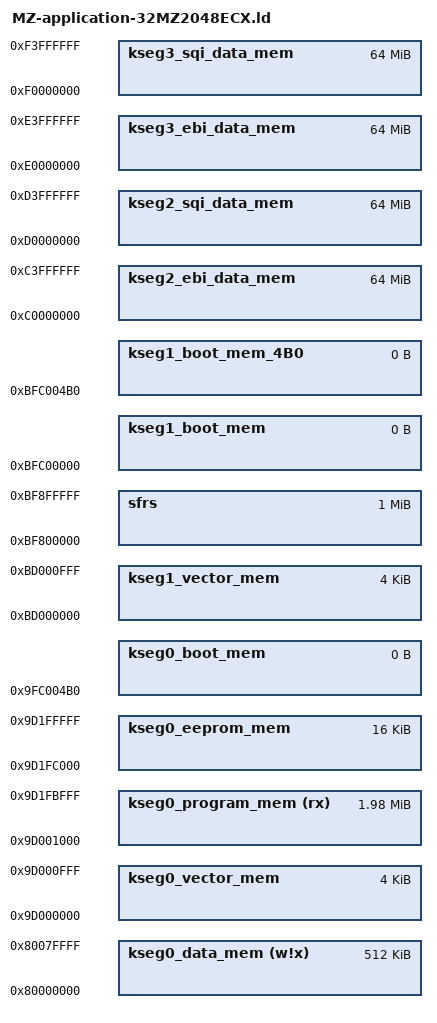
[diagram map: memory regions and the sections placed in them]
/*--------------------------------------------------------------------------
 * MPLAB XC Compiler -  PIC32MZ2048ECH100 linker script
 *
 * This software is developed by Microchip Technology Inc. and its
 * subsidiaries ("Microchip").
 *
 * Redistribution and use in source and binary forms, with or without
 * modification, are permitted provided that the following conditions are
 * met:
 *
 * 1.      Redistributions of source code must retain the above copyright
 *         notice, this list of conditions and the following disclaimer.
 * 2.      Redistributions in binary form must reproduce the above
 *         copyright notice, this list of conditions and the following
 *         disclaimer in the documentation and/or other materials provided
 *         with the distribution.
 * 3.      Microchip's name may not be used to endorse or promote products
 *         derived from this software without specific prior written
 *         permission.
 *
 * THIS SOFTWARE IS PROVIDED BY MICROCHIP "AS IS" AND ANY EXPRESS OR IMPLIED
 * WARRANTIES, INCLUDING, BUT NOT LIMITED TO, THE IMPLIED WARRANTIES OF
 * MERCHANTABILITY AND FITNESS FOR PURPOSE ARE DISCLAIMED. IN NO EVENT
 * SHALL MICROCHIP BE LIABLE FOR ANY DIRECT, INDIRECT, INCIDENTAL, SPECIAL,
 * EXEMPLARY, OR CONSEQUENTIAL DAMAGES (INCLUDING BUT NOT LIMITED TO
 * PROCUREMENT OF SUBSTITUTE GOODS OR SERVICES; LOSS OF USE, DATA OR PROFITS;
 * OR BUSINESS INTERRUPTION) HOWSOEVER CAUSED AND ON ANY THEORY OF LIABILITY,
 * WHETHER IN CONTRACT, STRICT LIABILITY, OR TORT (INCLUDING NEGLIGENCE OR
 * OTHERWISE) ARISING IN ANY WAY OUT OF THE USE OF THIS SOFTWARE, EVEN IF
 * ADVISED OF THE POSSIBILITY OF SUCH DAMAGE.
 *
 *-------------------------------------------------------------------------*/

/* Default linker script, for normal executables */

/*  NOTE: This single-file linker script replaces the two-file system used
 *  for older PIC32 devices.
 */

OUTPUT_FORMAT("elf32-tradlittlemips")
OUTPUT_ARCH(pic32mx)
ENTRY(_reset)
/*
 * Provide for a minimum stack and heap size
 * - _min_stack_size - represents the minimum space that must be made
 *                     available for the stack.  Can be overridden from
 *                     the command line using the linker's --defsym option.
 * - _min_heap_size  - represents the minimum space that must be made
 *                     available for the heap.  Must be specified on
 *                     the command line using the linker's --defsym option.
 */
EXTERN (_min_stack_size _min_heap_size)
PROVIDE(_min_stack_size = 4112) ;
PROVIDE(_min_heap_size = 449000) ;

/*************************************************************************
 * Processor-specific object file.  Contains SFR definitions.
 *************************************************************************/
INPUT("processor.o")

/*************************************************************************
 * Processor-specific peripheral libraries are optional
 *************************************************************************/
OPTIONAL("libmchp_peripheral.a")
OPTIONAL("libmchp_peripheral_32MZ2048ECH100.a")

/*************************************************************************
 * Vector-offset initialization
 *************************************************************************/
OPTIONAL("vector_offset_init.o")

MEMORY
{
  kseg0_vector_mem            : ORIGIN = 0x9D000000, LENGTH = 0x1000
  kseg1_vector_mem            : ORIGIN = 0xBD000000, LENGTH = 0x1000
  kseg0_program_mem    (rx)   : ORIGIN = 0x9D001000, LENGTH = 0x1FB000
  kseg0_eeprom_mem            : ORIGIN = 0x9D1FC000, LENGTH = 0x4000
  kseg0_boot_mem              : ORIGIN = 0x9FC004B0, LENGTH = 0x0
  kseg1_boot_mem              : ORIGIN = 0xBFC00000, LENGTH = 0x0
  kseg1_boot_mem_4B0          : ORIGIN = 0xBFC004B0, LENGTH = 0x0
  kseg0_data_mem       (w!x)  : ORIGIN = 0x80000000, LENGTH = 0x80000
  sfrs                        : ORIGIN = 0xBF800000, LENGTH = 0x100000
  kseg2_ebi_data_mem          : ORIGIN = 0xC0000000, LENGTH = 0x4000000
  kseg2_sqi_data_mem          : ORIGIN = 0xD0000000, LENGTH = 0x4000000
  kseg3_ebi_data_mem          : ORIGIN = 0xE0000000, LENGTH = 0x4000000
  kseg3_sqi_data_mem          : ORIGIN = 0xF0000000, LENGTH = 0x4000000
}

/*************************************************************************
 * Memory Address Equates
 * _RESET_ADDR                    -- Reset Vector
 * _BEV_EXCPT_ADDR                -- Boot exception Vector
 * _DBG_EXCPT_ADDR                -- In-circuit Debugging Exception Vector
 * _SIMPLE_TLB_REFILL_EXCPT_ADDR  -- Simple TLB-Refill Exception Vector
 * _CACHE_ERR_EXCPT_ADDR          -- Cache-error Exception Vector
 * _GEN_EXCPT_ADDR                -- General Exception Vector
 *************************************************************************/

/*************************************************************************
 * Memory Address Equates
 *************************************************************************/
_BEV_EXCPT_ADDR                 = 0xBFC00380;
_DBG_EXCPT_ADDR                 = 0xBFC00480;

_SIMPLE_TLB_REFILL_EXCPT_OFFSET = 0x0;
_TLB_TABLE_OFFSET               = 0x0A0;
_IMAGE_PTR_TABLE_OFFSET         = 0x0F8;
_IMAGE_HEADER_OFFSET            = 0x0FC;
_CACHE_ERR_EXCPT_OFFSET         = 0x100;
_GEN_EXCPT_OFFSET               = 0x180;

_ebase_address = ORIGIN(kseg0_vector_mem);

/*************************************************************************
 * Setting the _RESET_ADDR defines where the sketch start address will be
 * But make sure the MAP set the appropriate kseg0 placement and sizes
 * that is, you will need to place the kseg0_vecotr_memory too.
 *************************************************************************/
_RESET_ADDR                     = ORIGIN(kseg0_program_mem);
_SIMPLE_TLB_REFILL_EXCPT_ADDR   = _ebase_address + _SIMPLE_TLB_REFILL_EXCPT_OFFSET;
_TLB_TABLE                      = ORIGIN(kseg1_vector_mem) + _TLB_TABLE_OFFSET;
_CACHE_ERR_EXCPT_ADDR           = _ebase_address + _CACHE_ERR_EXCPT_OFFSET;
_GEN_EXCPT_ADDR                 = _ebase_address + _GEN_EXCPT_OFFSET;
_IMAGE_PTR_TABLE                = _ebase_address + _IMAGE_PTR_TABLE_OFFSET;
_IMAGE_HEADER_ADDR              = _ebase_address + _IMAGE_HEADER_OFFSET;
_EEPROM_ADDR                    = ORIGIN(kseg0_eeprom_mem);

/*************************************************************************
 *  Bootloader program directives.
 *  
 * _IMAGE_TYPE
 *
 *  image type:
 */
     
_imageReserved                      = 0x00000000 ;
_imageMPIDE                         = 0x00000001 ;  /* This is a normal MPIDE sketch                                                                                                    */
_imageBootFlashBootloader           = 0x00000002 ;  /* This is a boot flash bootloader                                                                                                  */
_imageProgramFlashBootloader        = 0x00000004 ;  /* This is a program flash bootloader                                                                                               */
_imageSplitFlashBootloader          = 0x00000008 ;  /* This has bootloader code in both boot and program flash                                                                          */

 /*
 *  Instructions for the bootloader
 */
                                                                       
_imageFullFlashEraseLess4KEEProm    = 0x00010000 ;  /* The original bootloader method of erasing all of program flash except the last 4K reserved for eeprom                            */
_imageJustInTimeFlashErase          = 0x00020000 ;  /* Only flash pages written too needed by the sketch is erased                                                                      */
_imageLinkerSpecifiedFlashErase     = 0x00040000 ;  /* The linker defines the flash range to erase                                                                                      */
_imageFullFlashErase                = 0x00080000 ;  /* All of flash is erased                                                                                                           */
_imageExecutionJumpAddress          = 0x01000000 ;  /* the bootloader will jump to the execution jump address immediately after programming                                             */
_imageExecutionJumpToFirstInFlash   = 0x02000000 ;  /* the bootloader will jump to the first sketch loaded in flash ignoring the execution jump address immediately after programming   */
 
/*  
 * _IMAGE_FLASH_SIZE 
 *
 *      Typically _imageJustInTimeFlashErase is selected to just erase the pages
 *      of flash that code is written too; thus leaving all other flash pages untouched.
 *  
 *      If _imageLinkerSpecifiedFlashErase set, then the range
 *      starting from _ebase_address for _IMAGE_FLASH_SIZE bytes are erased.
 *
 *      If _imageFullFlashErase is specified, than the whole flash
 *      as known by the bootloader will be erased. This will erase eeprom as well
 *
 *      if _imageFullFlashEraseLess4KEEProm is set, all of flash less the last 4K is
 *      erased, this is the old default. This bit could be set to make a program flash bootloader
 *      erasing everything but the old flash. If NOTHING is set, this will be the default as this is the old behavior.
 *  
 *  _JUMP_ADDR
 *  
 *      This is the address that the bootloader will jump to start execution
 *      of the sketch. This is almost always _RESET_ADDR.
 *
 *      However, you can specify an alternate entry execution point for example
 *      if you have alternate starup code that, say, shared
 *      the runtime with other sketches or needed some kind of specific handling
 *
 *      Immediately after programming (avrdude upload) the bootloader will typically
 *      jump to the just loaded sketch, no matter where it was loaded in flash.
 *      _imageExecutionJumpToFirstInFlash will tell the bootloader to jump to the first
 *      sketch in flash even if the just loaded one is not at the beginning of flash.
 *      This is useful when programming sketches in slots of flash and then always
 *      jumping to the program-flash loader (vector sketch) as if the board was just reset.
 *      This bit does not effect jumping to a sketch already in flash after reset.
 *      As of today, after reset, the first program in flash will always be jumped to.
 *
 *************************************************************************/
 _IMAGE_TYPE            = _imageMPIDE | _imageJustInTimeFlashErase | _imageExecutionJumpAddress;
 _IMAGE_FLASH_SIZE      = LENGTH(kseg0_vector_mem) + LENGTH(kseg0_program_mem);
 _JUMP_ADDR             = _RESET_ADDR;


/* From here out every linker script is the same, so just include it */
/*INCLUDE "chipKIT-application-COMMON.ld"*/
